# MK10D5 register map
Vendor: Freescale Semiconductor, Inc.; File version: 1.6
CPU: CM4 r0p1, little endian, no MPU, no FPU, 0x4 interrupt priority bits, 0x0 interrupts
Registers are 32-bit, read-write, reset 0x0 unless marked. A register's access mark holds for its fields unless they carry their own. Offsets are from the block's base; [hi:lo] are bit positions; {n}, {i} and the like mark numbered series; 'fields as' and 'values as' point back to an identical list.

## I2S0 — Inter-IC Sound / Synchronous Audio Interface
Base 0x4002F000; register names take the prefix I2S0_
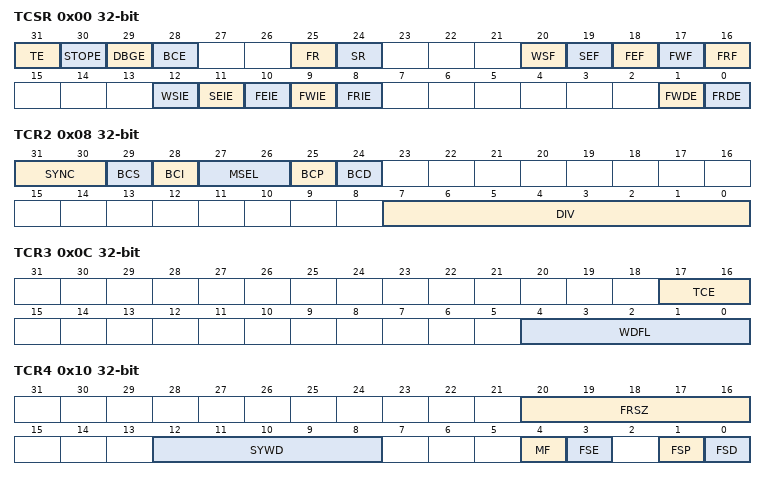
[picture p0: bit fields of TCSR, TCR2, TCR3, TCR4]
0x00 TCSR — SAI Transmit Control Register
  [31] TE — Transmitter enable
    0=Transmitter is disabled; 1=Transmitter is enabled, or transmitter has been disabled and not end of frame
  [30] STOPE — Stop enable
    0=Transmitter disabled in stop mode; 1=Transmitter enabled in stop mode
  [29] DBGE — Debug enable
    0=Transmitter is disabled in debug mode, after completing the current frame; 1=Transmitter is enabled in debug mode
  [28] BCE — Bit Clock Enable
    0=Transmit bit clock is disabled; 1=Transmit bit clock is enabled
  [25] FR wo — FIFO reset
    0=No effect; 1=FIFO reset
  [24] SR — Software reset
    0=No effect; 1=Software reset
  [20] WSF — Word start flag
    0=Start of word not detected; 1=Start of word detected
  [19] SEF — Sync error flag
    0=Sync error not detected; 1=Frame sync error detected
  [18] FEF — FIFO error flag
    0=Transmit underrun not detected; 1=Transmit underrun detected
  [17] FWF ro — FIFO warning flag
    0=No enabled transmit FIFO is empty; 1=Enabled transmit FIFO is empty
  [16] FRF ro — FIFO request flag
    0=Transmit FIFO watermark not reached; 1=Transmit FIFO watermark has been reached
  [12] WSIE — Word start interrupt enable
    0=Disables interrupt; 1=Enables interrupt
  [11] SEIE — Sync error interrupt enable
    0=Disables interrupt; 1=Enables interrupt
  [10] FEIE — FIFO error interrupt enable
    0=Disables the interrupt,; 1=Enables the interrupt
  [9] FWIE — FIFO warning interrupt enable
    0=Disables the interrupt; 1=Enables the interrupt
  [8] FRIE — FIFO request interrupt enable
    0=Disables the interrupt; 1=Enables the interrupt
  [1] FWDE — FIFO warning DMA enable
    0=Disables the DMA request; 1=Enables the DMA request
  [0] FRDE — FIFO request DMA enable
    0=Disables the DMA request; 1=Enables the DMA request
0x04 TCR1 — SAI Transmit Configuration 1 Register
  [2:0] TFW — Transmit FIFO watermark
0x08 TCR2 — SAI Transmit Configuration 2 Register
  [31:30] SYNC — Synchronous Mode
    0=Asynchronous mode; 1=Synchronous with receiver; 2=Synchronous with another SAI transmitter; 3=Synchronous with another SAI receiver
  [29] BCS — Bit Clock Swap
    0=Use the normal bit clock source; 1=Swap the bit clock source
  [28] BCI — Bit Clock Input
    0=No effect; 1=Internal logic is clocked by external bit clock
  [27:26] MSEL — MCLK Select
    0=Bus Clock selected; 1=Master Clock 1 selected; 2=Master Clock 2 selected; 3=Master Clock 3 selected
  [25] BCP — Bit clock polarity
    0=Bit Clock is active high (drive outputs on rising edge and sample inputs on falling edge); 1=Bit Clock is active low (drive outputs on falling edge and sample inputs on rising edge)
  [24] BCD — Bit clock direction
    0=Bit clock is generated externally (slave mode); 1=Bit clock is generated internally (master mode)
  [7:0] DIV — Bit clock divide
0x0C TCR3 — SAI Transmit Configuration 3 Register
  [17:16] TCE — Transmit channel enable
  [4:0] WDFL — Word flag configuration
0x10 TCR4 — SAI Transmit Configuration 4 Register
  [20:16] FRSZ — Frame size
  [12:8] SYWD — Sync width
  [4] MF — MSB first
    0=LBS is transmitted/received first; 1=MBS is transmitted/received first
  [3] FSE — Frame sync early
    0=Frame sync asserts with the first bit of the frame; 1=Frame sync asserts one bit before the first bit of the frame
  [1] FSP — Frame sync polarity
    0=Frame sync is active high; 1=Frame sync is active low
  [0] FSD — Frame sync direction
    0=Frame Sync is generated externally (slave mode); 1=Frame Sync is generated internally (master mode)
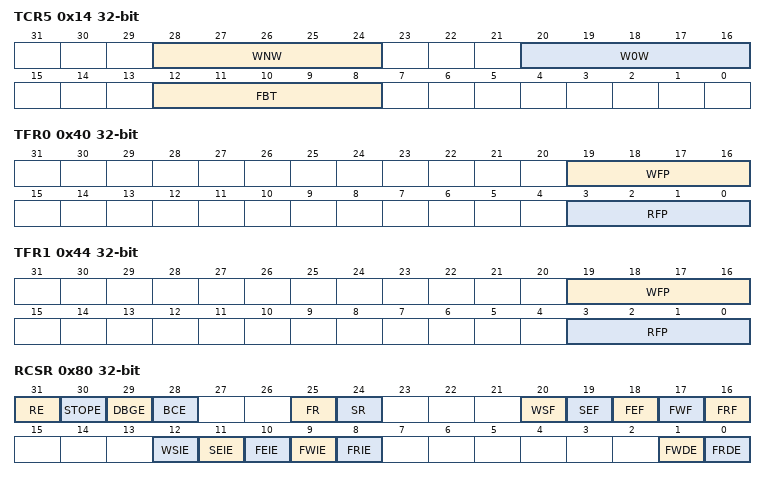
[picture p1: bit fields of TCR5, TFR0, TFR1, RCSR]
0x14 TCR5 — SAI Transmit Configuration 5 Register
  [28:24] WNW — Word N width
  [20:16] W0W — Word 0 width
  [12:8] FBT — First bit shifted
0x20 TDR0 wo — SAI Transmit Data Register
  [31:0] TDR — Transmit data register
0x24 TDR1 wo — SAI Transmit Data Register
  [31:0] TDR — Transmit data register
0x40 TFR0 ro — SAI Transmit FIFO Register
  [19:16] WFP — Write FIFO pointer
  [3:0] RFP — Read FIFO pointer
0x44 TFR1 ro — SAI Transmit FIFO Register
  [19:16] WFP — Write FIFO pointer
  [3:0] RFP — Read FIFO pointer
0x60 TMR — SAI Transmit Mask Register
  [31:0] TWM — Transmit word mask
    0=Word N is enabled; 1=Word N is masked. The transmit data pins are tri-stated when masked.
0x80 RCSR — SAI Receive Control Register
  [31] RE — Receiver enable
    0=Receiver is disabled; 1=Receiver is enabled, or receiver has been disabled and not end of frame
  [30] STOPE — Stop enable
    0=Receiver disabled in stop mode; 1=Receiver enabled in stop mode
  [29] DBGE — Debug enable
    0=Receiver is disabled in debug mode, after completing the current frame; 1=Receiver is enabled in debug mode
  [28] BCE — Bit Clock enable
    0=Receive bit clock is disabled; 1=Receive bit clock is enabled
  [25] FR wo — FIFO reset
    0=No effect; 1=FIFO reset
  [24] SR — Software reset
    0=No effect; 1=Software reset
  [20] WSF — Word start flag
    0=Start of word not detected; 1=Start of word detected
  [19] SEF — Sync error flag
    0=Sync error not detected; 1=Frame sync error detected
  [18] FEF — FIFO error flag
    0=Receive overflow not detected; 1=Receive overflow detected
  [17] FWF ro — FIFO warning flag
    0=No enabled receive FIFO is full; 1=Enabled receive FIFO is full
  [16] FRF ro — FIFO request flag
    0=Receive FIFO watermark not reached; 1=Receive FIFO watermark has been reached
  [12] WSIE — Word start interrupt enable
    0=Disables interrupt; 1=Enables interrupt
  [11] SEIE — Sync error interrupt enable
    0=Disables interrupt; 1=Enables interrupt
  [10] FEIE — FIFO error interrupt enable
    0=Disables the interrupt,; 1=Enables the interrupt
  [9] FWIE — FIFO warning interrupt enable
    0=Disables the interrupt; 1=Enables the interrupt
  [8] FRIE — FIFO request interrupt enable
    0=Disables the interrupt; 1=Enables the interrupt
  [1] FWDE — FIFO warning DMA enable
    0=Disables the DMA request; 1=Enables the DMA request
  [0] FRDE — FIFO request DMA enable
    0=Disables the DMA request; 1=Enables the DMA request
0x84 RCR1 — SAI Receive Configuration 1 Register
  [2:0] RFW — Receive FIFO watermark
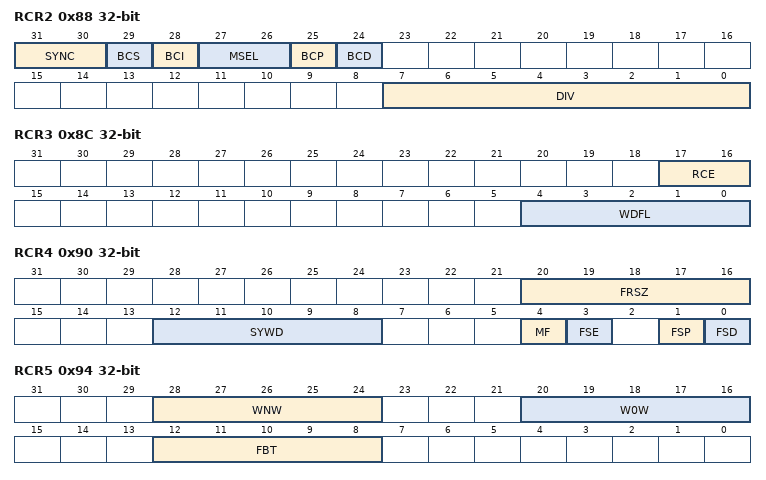
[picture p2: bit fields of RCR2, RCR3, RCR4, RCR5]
0x88 RCR2 — SAI Receive Configuration 2 Register
  [31:30] SYNC — Synchronous Mode
    0=Asynchronous mode; 1=Synchronous with transmitter; 2=Synchronous with another SAI receiver; 3=Synchronous with another SAI transmitter
  [29] BCS — Bit Clock Swap
    values as TCR2.BCS
  [28] BCI — Bit Clock Input
    0=No effect; 1=Internal logic is clocked as if bit clock was externally generated
  [27:26] MSEL — MCLK Select
    values as TCR2.MSEL
  [25] BCP — Bit clock polarity
    values as TCR2.BCP
  [24] BCD — Bit clock direction
    values as TCR2.BCD
  [7:0] DIV — Bit clock divide
0x8C RCR3 — SAI Receive Configuration 3 Register
  [17:16] RCE — Receive channel enable
  [4:0] WDFL — Word flag configuration
0x90 RCR4 — SAI Receive Configuration 4 Register
  fields as TCR4
0x94 RCR5 — SAI Receive Configuration 5 Register
  fields as TCR5
0xA0 RDR0 ro — SAI Receive Data Register
  [31:0] RDR — Receive data register
0xA4 RDR1 ro — SAI Receive Data Register
  [31:0] RDR — Receive data register
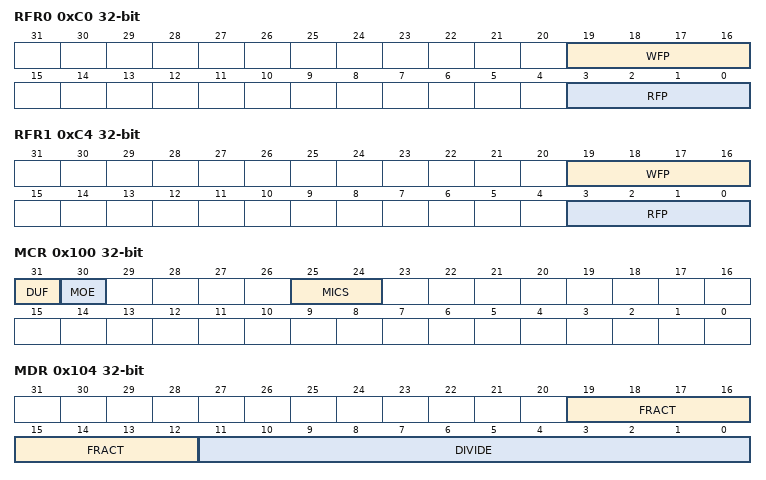
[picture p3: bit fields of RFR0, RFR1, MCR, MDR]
0xC0 RFR0 ro — SAI Receive FIFO Register
  [19:16] WFP — Write FIFO pointer
  [3:0] RFP — Read FIFO pointer
0xC4 RFR1 ro — SAI Receive FIFO Register
  [19:16] WFP — Write FIFO pointer
  [3:0] RFP — Read FIFO pointer
0xE0 RMR — SAI Receive Mask Register
  [31:0] RWM — Receive word mask
    0=Word N is enabled; 1=Word N is masked
0x100 MCR — SAI MCLK Control Register
  [31] DUF ro — Divider Update Flag
    0=MCLK Divider ratio is not being updated currently; 1=MCLK Divider ratio is updating on-the-fly. Furthur updates to the MCLK Divider ratio are blocked while this flag remains set.
  [30] MOE — MCLK Output Enable
    0=SAI_MCLK pin is configured as an input that bypasses the MCLK Divider; 1=SAI_MCLK pin is configured as an output from the MCLK Divider and the MCLK Divider is enabled
  [25:24] MICS — MCLK Input Clock Select
    {v}=MCLK Divider input clock {v} selected (v=0..3)
0x104 MDR — MCLK Divide Register
  [19:12] FRACT — MCLK Fraction
  [11:0] DIVIDE — MCLK Divide
